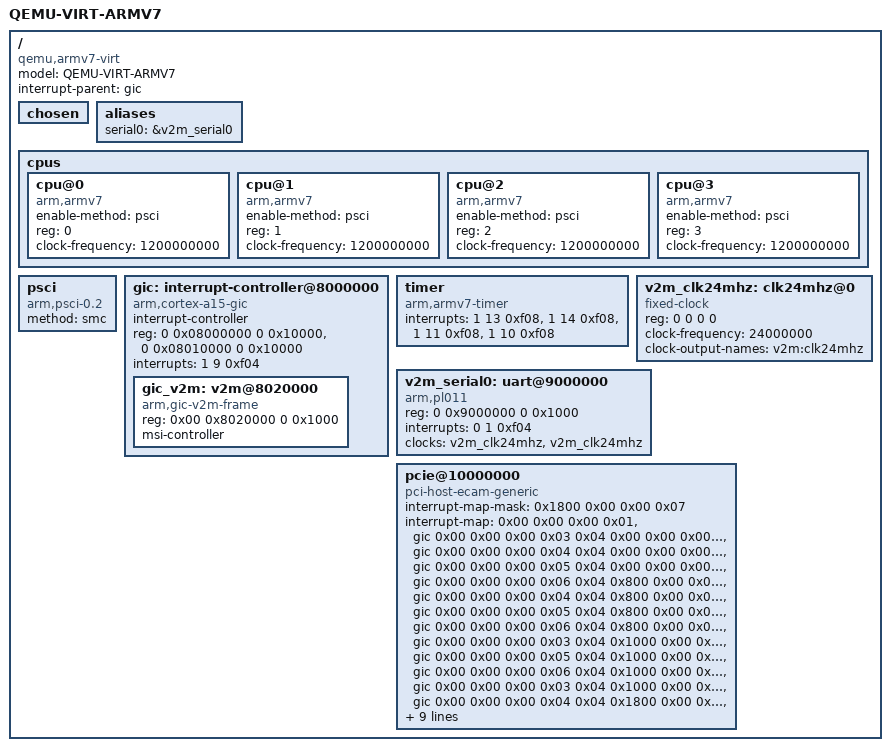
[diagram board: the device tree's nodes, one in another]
// SPDX-License-Identifier: Apache-2.0
/*
 * Copyright (c) 2019 Xing Loong <xing.xl.loong@gmail.com>
 * QEMU-Virt-ARMv7 (CA15x4 or CA7x4)
 */

/dts-v1/;

#include "memory.dtsi"

/ {
	model = "QEMU-VIRT-ARMV7";
	compatible = "qemu,armv7-virt";
	interrupt-parent = <&gic>;
	#address-cells = <2>;
	#size-cells = <2>;

	chosen { };

	aliases {
		serial0 = &v2m_serial0;
	};

	cpus {
		#address-cells = <1>;
		#size-cells = <0>;

		cpu@0 {
			device_type = "cpu";
			compatible = "arm,armv7";
			enable-method = "psci";
			reg = <0>;
			clock-frequency = <1200000000>;
		};

		cpu@1 {
			device_type = "cpu";
			compatible = "arm,armv7";
			enable-method = "psci";
			reg = <1>;
			clock-frequency = <1200000000>;
		};

		cpu@2 {
			device_type = "cpu";
			compatible = "arm,armv7";
			enable-method = "psci";
			reg = <2>;
			clock-frequency = <1200000000>;
		};

		cpu@3 {
			device_type = "cpu";
			compatible = "arm,armv7";
			enable-method = "psci";
			reg = <3>;
			clock-frequency = <1200000000>;
		};
	};

	psci {
		compatible = "arm,psci-0.2";
		method = "smc";
	};

	gic: interrupt-controller@8000000 {
		compatible = "arm,cortex-a15-gic", "arm,cortex-a7-gic";
		#interrupt-cells = <3>;
		interrupt-controller;
		reg = <0 0x08000000 0 0x10000>,
			  <0 0x08010000 0 0x10000>;

		interrupts = <1 9 0xf04>;

		#address-cells = <2>;
		#size-cells = <2>;

		gic_v2m: v2m@8020000 {
			reg = <0x00 0x8020000 0 0x1000>;
			msi-controller;
			compatible = "arm,gic-v2m-frame";
		};
	};

	timer {
		compatible = "arm,armv7-timer";
		interrupts = <1 13 0xf08>,
				 <1 14 0xf08>,
				 <1 11 0xf08>,
				 <1 10 0xf08>;
	};

	v2m_clk24mhz: clk24mhz@0 {
		compatible = "fixed-clock";
		#clock-cells = <0>;
		reg = <0 0 0 0>;
		clock-frequency = <24000000>;
		clock-output-names = "v2m:clk24mhz";
	};

	v2m_serial0: uart@9000000 {
		compatible = "arm,pl011", "arm,primecell";
		reg = <0 0x9000000 0 0x1000>;
		interrupts = <0 1 0xf04>;
		clocks = <&v2m_clk24mhz>, <&v2m_clk24mhz>;
		clock-names = "uartclk", "apb_pclk";
	};

	pcie@10000000 {
		interrupt-map-mask = <0x1800 0x00 0x00 0x07>;
		interrupt-map = <
				0x00 0x00 0x00 0x01 &gic 0x00 0x00 0x00 0x03 0x04
				0x00 0x00 0x00 0x02 &gic 0x00 0x00 0x00 0x04 0x04
				0x00 0x00 0x00 0x03 &gic 0x00 0x00 0x00 0x05 0x04
				0x00 0x00 0x00 0x04 &gic 0x00 0x00 0x00 0x06 0x04
				0x800 0x00 0x00 0x01 &gic 0x00 0x00 0x00 0x04 0x04
				0x800 0x00 0x00 0x02 &gic 0x00 0x00 0x00 0x05 0x04
				0x800 0x00 0x00 0x03 &gic 0x00 0x00 0x00 0x06 0x04
				0x800 0x00 0x00 0x04 &gic 0x00 0x00 0x00 0x03 0x04
				0x1000 0x00 0x00 0x01 &gic 0x00 0x00 0x00 0x05 0x04
				0x1000 0x00 0x00 0x02 &gic 0x00 0x00 0x00 0x06 0x04
				0x1000 0x00 0x00 0x03 &gic 0x00 0x00 0x00 0x03 0x04
				0x1000 0x00 0x00 0x04 &gic 0x00 0x00 0x00 0x04 0x04
				0x1800 0x00 0x00 0x01 &gic 0x00 0x00 0x00 0x06 0x04
				0x1800 0x00 0x00 0x02 &gic 0x00 0x00 0x00 0x03 0x04
				0x1800 0x00 0x00 0x03 &gic 0x00 0x00 0x00 0x04 0x04
				0x1800 0x00 0x00 0x04 &gic 0x00 0x00 0x00 0x05 0x04>;
		#interrupt-cells = <0x01>;
		ranges = <0x1000000 0x00 0x00 0x00 0x3eff0000 0x00 0x10000
			0x2000000 0x00 0x10000000 0x00 0x10000000 0x00 0x2eff0000
			0x3000000 0x80 0x00 0x80 0x00 0x80 0x00>;
		reg = <0x40 0x10000000 0 0x10000000>;
		msi-map = <0x00 &gic_v2m 0x00 0x10000>;
		dma-coherent;
		bus-range = <0x00 0xff>;
		linux,pci-domain = <0x00>;
		#size-cells = <0x02>;
		#address-cells = <0x03>;
		device_type = "pci";
		compatible = "pci-host-ecam-generic";
	};
};
